# APM32F446 register map
File version: 1.0
CPU: CM4 r0p1, little endian, MPU, FPU, 4 interrupt priority bits
Registers are 32-bit, read-write, reset 0x0 unless marked. A register's access mark holds for its fields unless they carry their own. Offsets are from the block's base; [hi:lo] are bit positions; {n}, {i} and the like mark numbered series; 'fields as' and 'values as' point back to an identical list.

## AC — Access Controller
Base 0x40000000
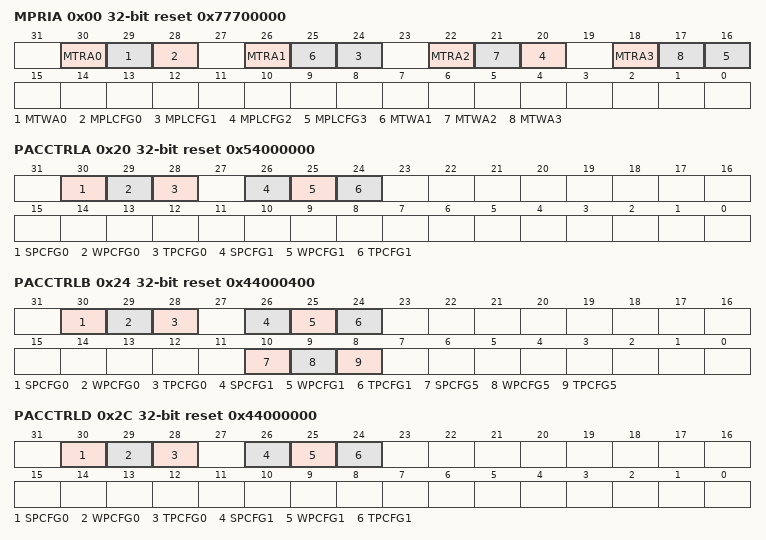
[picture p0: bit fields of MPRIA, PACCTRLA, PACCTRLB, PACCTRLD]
0x00 MPRIA reset 0x77700000 — Master Privilege Register A
  [30] MTRA0 — Master 0 Trusted For Read
    0=This master is not trusted for read accesses; 1=This master is trusted for read accesses
  [29] MTWA0 — Master 0 Trusted For Writes
    0=This master is not trusted for write accesses; 1=This master is trusted for write accesses
  [28-4n] MPLCFG{n} (n=0..3) — Master {n} Privilege Level Configure
    0=Accesses from this master are forced to user-mode; 1=Accesses from this master are not forced to user-mode
  [26] MTRA1 — Master 1 Trusted for Read
    values as MTRA0
  [25] MTWA1 — Master 1 Trusted for Writes
    values as MTWA0
  [22] MTRA2 — Master 2 Trusted For Read
    values as MTRA0
  [21] MTWA2 — Master 2 Trusted For Writes
    values as MTWA0
  [18] MTRA3 — Master 3 Trusted For Read
    values as MTRA0
  [17] MTWA3 — Master 3 Trusted For Writes
    values as MTWA0
0x20 PACCTRLA reset 0x54000000 — Peripheral Access Control Register A
  [30] SPCFG0 — Supervisor Protect Configure
    0=This peripheral does not require supervisor privilege level for accesses; 1=This peripheral requires supervisor privilege level for accesses
  [29] WPCFG0 — Write Protect Configure
    0=This peripheral allows write accesses; 1=This peripheral is write protected
  [28] TPCFG0 — Trusted Protect Configure
    0=Accesses from an untrusted master are allowed; 1=Accesses from an untrusted master are not allowed
  [26] SPCFG1 — Supervisor Protect Configure
    values as SPCFG0
  [25] WPCFG1 — Write Protect Configure
    values as WPCFG0
  [24] TPCFG1 — Trusted Protect Configure
    values as TPCFG0
0x24 PACCTRLB reset 0x44000400 — Peripheral Access Control Register B
  [30] SPCFG0 — Supervisor Protect Configure
    values as PACCTRLA.SPCFG0
  [29] WPCFG0 — Write Protect Configure
    values as PACCTRLA.WPCFG0
  [28] TPCFG0 — Trusted Protect Configure
    values as PACCTRLA.TPCFG0
  [26] SPCFG1 — Supervisor Protect Configure
    values as PACCTRLA.SPCFG0
  [25] WPCFG1 — Write Protect Configure
    values as PACCTRLA.WPCFG0
  [24] TPCFG1 — Trusted Protect Configure
    values as PACCTRLA.TPCFG0
  [10] SPCFG5 — Supervisor Protect Configure
    values as PACCTRLA.SPCFG0
  [9] WPCFG5 — Write Protect Configure
    values as PACCTRLA.WPCFG0
  [8] TPCFG5 — Trusted Protect Configure
    values as PACCTRLA.TPCFG0
0x2C PACCTRLD reset 0x44000000 — Peripheral Access Control Register D
  fields as PACCTRLA
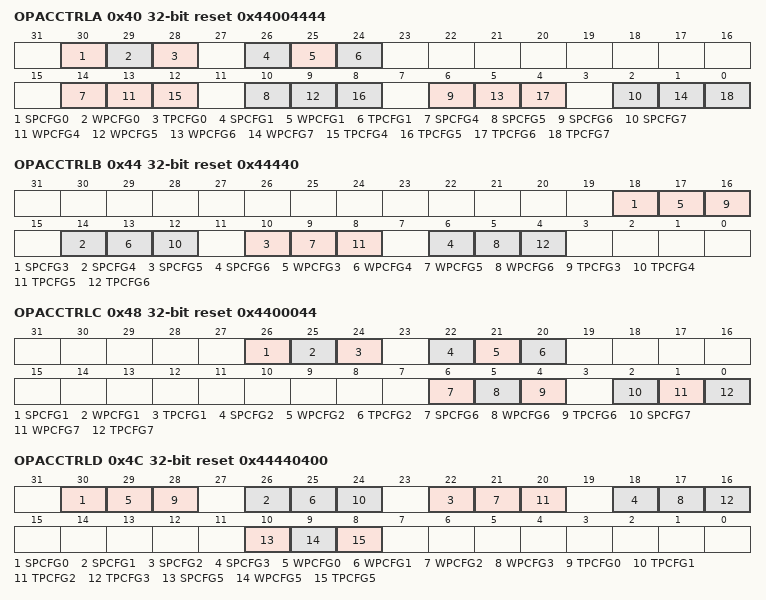
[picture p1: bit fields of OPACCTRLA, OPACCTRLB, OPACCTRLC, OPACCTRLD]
0x40 OPACCTRLA reset 0x44004444 — Off-Platform Peripheral Access Control Register A
  [30] SPCFG0 — Supervisor Protect Configure
    values as PACCTRLA.SPCFG0
  [29] WPCFG0 — Write Protect Configure
    values as PACCTRLA.WPCFG0
  [28] TPCFG0 — Trusted Protect Configure
    values as PACCTRLA.TPCFG0
  [26] SPCFG1 — Supervisor Protect Configure
    values as PACCTRLA.SPCFG0
  [25] WPCFG1 — Write Protect Configure
    values as PACCTRLA.WPCFG0
  [24] TPCFG1 — Trusted Protect Configure
    values as PACCTRLA.TPCFG0
  [30-4n] SPCFG{n} (n=4..7) — Supervisor Protect Configure
    values as PACCTRLA.SPCFG0
  [29-4n] WPCFG{n} (n=4..7) — Write Protect Configure
    values as PACCTRLA.WPCFG0
  [28-4n] TPCFG{n} (n=4..7) — Trusted Protect Configure
    values as PACCTRLA.TPCFG0
0x44 OPACCTRLB reset 0x44440 — Off-Platform Peripheral Access Control Register B
  [30-4n] SPCFG{n} (n=3..6) — Supervisor Protect Configure
    values as PACCTRLA.SPCFG0
  [29-4n] WPCFG{n} (n=3..6) — Write Protect Configure
    values as PACCTRLA.WPCFG0
  [28-4n] TPCFG{n} (n=3..6) — Trusted Protect Configure
    values as PACCTRLA.TPCFG0
0x48 OPACCTRLC reset 0x4400044 — Off-Platform Peripheral Access Control Register C
  [26] SPCFG1 — Supervisor Protect Configure
    values as PACCTRLA.SPCFG0
  [25] WPCFG1 — Write Protect Configure
    values as PACCTRLA.WPCFG0
  [24] TPCFG1 — Trusted Protect Configure
    values as PACCTRLA.TPCFG0
  [22] SPCFG2 — Supervisor Protect Configure
    values as PACCTRLA.SPCFG0
  [21] WPCFG2 — Write Protect Configure
    values as PACCTRLA.WPCFG0
  [20] TPCFG2 — Trusted Protect Configure
    values as PACCTRLA.TPCFG0
  [6] SPCFG6 — Supervisor Protect Configure
    values as PACCTRLA.SPCFG0
  [5] WPCFG6 — Write Protect Configure
    values as PACCTRLA.WPCFG0
  [4] TPCFG6 — Trusted Protect Configure
    values as PACCTRLA.TPCFG0
  [2] SPCFG7 — Supervisor Protect Configure
    values as PACCTRLA.SPCFG0
  [1] WPCFG7 — Write Protect Configure
    values as PACCTRLA.WPCFG0
  [0] TPCFG7 — Trusted Protect Configure
    values as PACCTRLA.TPCFG0
0x4C OPACCTRLD reset 0x44440400 — Off-Platform Peripheral Access Control Register D
  [30-4n] SPCFG{n} (n=0..3) — Supervisor Protect Configure
    values as PACCTRLA.SPCFG0
  [29-4n] WPCFG{n} (n=0..3) — Write Protect Configure
    values as PACCTRLA.WPCFG0
  [28-4n] TPCFG{n} (n=0..3) — Trusted Protect Configure
    values as PACCTRLA.TPCFG0
  [10] SPCFG5 — Supervisor Protect Configure
    values as PACCTRLA.SPCFG0
  [9] WPCFG5 — Write Protect Configure
    values as PACCTRLA.WPCFG0
  [8] TPCFG5 — Trusted Protect Configure
    values as PACCTRLA.TPCFG0
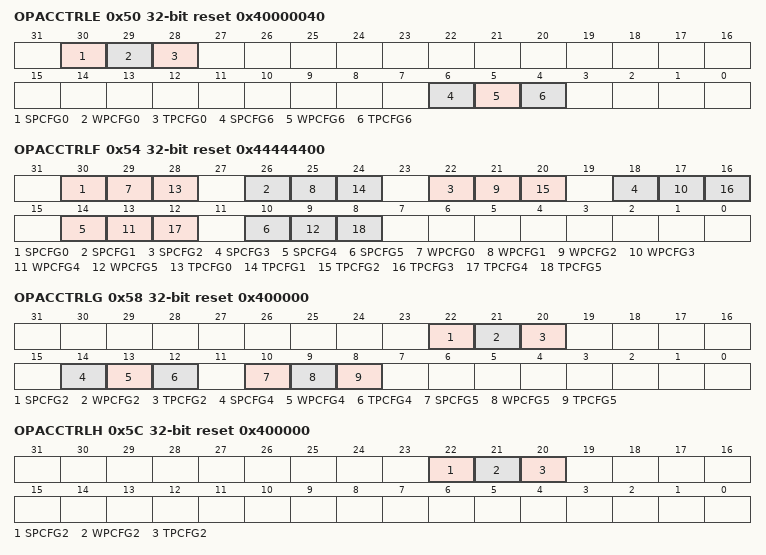
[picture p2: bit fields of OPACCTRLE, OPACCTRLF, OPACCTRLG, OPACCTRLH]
0x50 OPACCTRLE reset 0x40000040 — Off-Platform Peripheral Access Control Register E
  [30] SPCFG0 — Supervisor Protect Configure
    values as PACCTRLA.SPCFG0
  [29] WPCFG0 — Write Protect Configure
    values as PACCTRLA.WPCFG0
  [28] TPCFG0 — Trusted Protect Configure
    values as PACCTRLA.TPCFG0
  [6] SPCFG6 — Supervisor Protect Configure
    values as PACCTRLA.SPCFG0
  [5] WPCFG6 — Write Protect Configure
    values as PACCTRLA.WPCFG0
  [4] TPCFG6 — Trusted Protect Configure
    values as PACCTRLA.TPCFG0
0x54 OPACCTRLF reset 0x44444400 — Off-Platform Peripheral Access Control Register F
  [30-4n] SPCFG{n} (n=0..5) — Supervisor Protect Configure
    values as PACCTRLA.SPCFG0
  [29-4n] WPCFG{n} (n=0..5) — Write Protect Configure
    values as PACCTRLA.WPCFG0
  [28-4n] TPCFG{n} (n=0..5) — Trusted Protect Configure
    values as PACCTRLA.TPCFG0
0x58 OPACCTRLG reset 0x400000 — Off-Platform Peripheral Access Control Register G
  [22] SPCFG2 — Supervisor Protect Configure
    values as PACCTRLA.SPCFG0
  [21] WPCFG2 — Write Protect Configure
    values as PACCTRLA.WPCFG0
  [20] TPCFG2 — Trusted Protect Configure
    values as PACCTRLA.TPCFG0
  [14] SPCFG4 — Supervisor Protect Configure
    values as PACCTRLA.SPCFG0
  [13] WPCFG4 — Write Protect Configure
    values as PACCTRLA.WPCFG0
  [12] TPCFG4 — Trusted Protect Configure
    values as PACCTRLA.TPCFG0
  [10] SPCFG5 — Supervisor Protect Configure
    values as PACCTRLA.SPCFG0
  [9] WPCFG5 — Write Protect Configure
    values as PACCTRLA.WPCFG0
  [8] TPCFG5 — Trusted Protect Configure
    values as PACCTRLA.TPCFG0
0x5C OPACCTRLH reset 0x400000 — Off-Platform Peripheral Access Control Register H
  [22] SPCFG2 — Supervisor Protect Configure
    values as PACCTRLA.SPCFG0
  [21] WPCFG2 — Write Protect Configure
    values as PACCTRLA.WPCFG0
  [20] TPCFG2 — Trusted Protect Configure
    values as PACCTRLA.TPCFG0
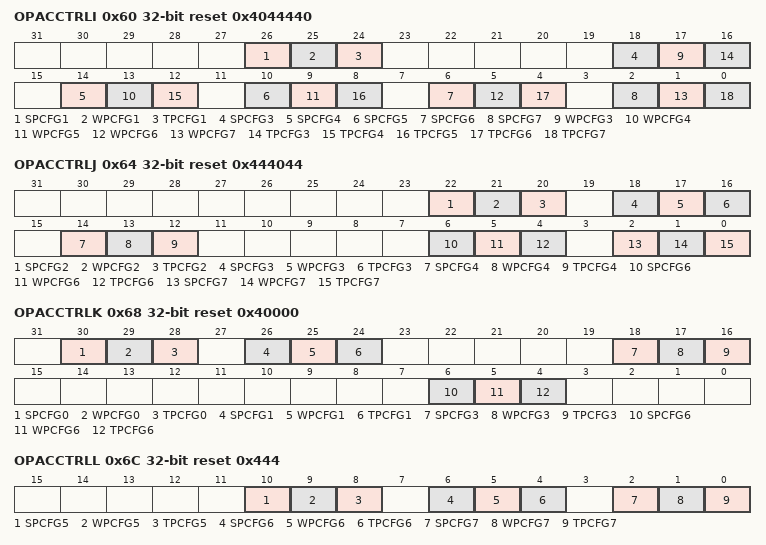
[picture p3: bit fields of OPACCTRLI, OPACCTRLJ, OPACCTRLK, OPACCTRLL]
0x60 OPACCTRLI reset 0x4044440 — Off-Platform Peripheral Access Control Register I
  [26] SPCFG1 — Supervisor Protect Configure
    values as PACCTRLA.SPCFG0
  [25] WPCFG1 — Write Protect Configure
    values as PACCTRLA.WPCFG0
  [24] TPCFG1 — Trusted Protect Configure
    values as PACCTRLA.TPCFG0
  [30-4n] SPCFG{n} (n=3..7) — Supervisor Protect Configure
    values as PACCTRLA.SPCFG0
  [29-4n] WPCFG{n} (n=3..7) — Write Protect Configure
    values as PACCTRLA.WPCFG0
  [28-4n] TPCFG{n} (n=3..7) — Trusted Protect Configure
    values as PACCTRLA.TPCFG0
0x64 OPACCTRLJ reset 0x444044 — Off-Platform Peripheral Access Control Register J
  [22] SPCFG2 — Supervisor Protect Configure
    values as PACCTRLA.SPCFG0
  [21] WPCFG2 — Write Protect Configure
    values as PACCTRLA.WPCFG0
  [20] TPCFG2 — Trusted Protect Configure
    values as PACCTRLA.TPCFG0
  [18] SPCFG3 — Supervisor Protect Configure
    values as PACCTRLA.SPCFG0
  [17] WPCFG3 — Write Protect Configure
    values as PACCTRLA.WPCFG0
  [16] TPCFG3 — Trusted Protect Configure
    values as PACCTRLA.TPCFG0
  [14] SPCFG4 — Supervisor Protect Configure
    values as PACCTRLA.SPCFG0
  [13] WPCFG4 — Write Protect Configure
    values as PACCTRLA.WPCFG0
  [12] TPCFG4 — Trusted Protect Configure
    values as PACCTRLA.TPCFG0
  [6] SPCFG6 — Supervisor Protect Configure
    values as PACCTRLA.SPCFG0
  [5] WPCFG6 — Write Protect Configure
    values as PACCTRLA.WPCFG0
  [4] TPCFG6 — Trusted Protect Configure
    values as PACCTRLA.TPCFG0
  [2] SPCFG7 — Supervisor Protect Configure
    values as PACCTRLA.SPCFG0
  [1] WPCFG7 — Write Protect Configure
    values as PACCTRLA.WPCFG0
  [0] TPCFG7 — Trusted Protect Configure
    values as PACCTRLA.TPCFG0
0x68 OPACCTRLK reset 0x40000 — Off-Platform Peripheral Access Control Register K
  [30] SPCFG0 — Supervisor Protect Configure
    values as PACCTRLA.SPCFG0
  [29] WPCFG0 — Write Protect Configure
    values as PACCTRLA.WPCFG0
  [28] TPCFG0 — Trusted Protect Configure
    values as PACCTRLA.TPCFG0
  [26] SPCFG1 — Supervisor Protect Configure
    values as PACCTRLA.SPCFG0
  [25] WPCFG1 — Write Protect Configure
    values as PACCTRLA.WPCFG0
  [24] TPCFG1 — Trusted Protect Configure
    values as PACCTRLA.TPCFG0
  [18] SPCFG3 — Supervisor Protect Configure
    values as PACCTRLA.SPCFG0
  [17] WPCFG3 — Write Protect Configure
    values as PACCTRLA.WPCFG0
  [16] TPCFG3 — Trusted Protect Configure
    values as PACCTRLA.TPCFG0
  [6] SPCFG6 — Supervisor Protect Configure
    values as PACCTRLA.SPCFG0
  [5] WPCFG6 — Write Protect Configure
    values as PACCTRLA.WPCFG0
  [4] TPCFG6 — Trusted Protect Configure
    values as PACCTRLA.TPCFG0
0x6C OPACCTRLL reset 0x444 — Off-Platform Peripheral Access Control Register L
  [10] SPCFG5 — Supervisor Protect Configure
    values as PACCTRLA.SPCFG0
  [9] WPCFG5 — Write Protect Configure
    values as PACCTRLA.WPCFG0
  [8] TPCFG5 — Trusted Protect Configure
    values as PACCTRLA.TPCFG0
  [6] SPCFG6 — Supervisor Protect Configure
    values as PACCTRLA.SPCFG0
  [5] WPCFG6 — Write Protect Configure
    values as PACCTRLA.WPCFG0
  [4] TPCFG6 — Trusted Protect Configure
    values as PACCTRLA.TPCFG0
  [2] SPCFG7 — Supervisor Protect Configure
    values as PACCTRLA.SPCFG0
  [1] WPCFG7 — Write Protect Configure
    values as PACCTRLA.WPCFG0
  [0] TPCFG7 — Trusted Protect Configure
    values as PACCTRLA.TPCFG0
